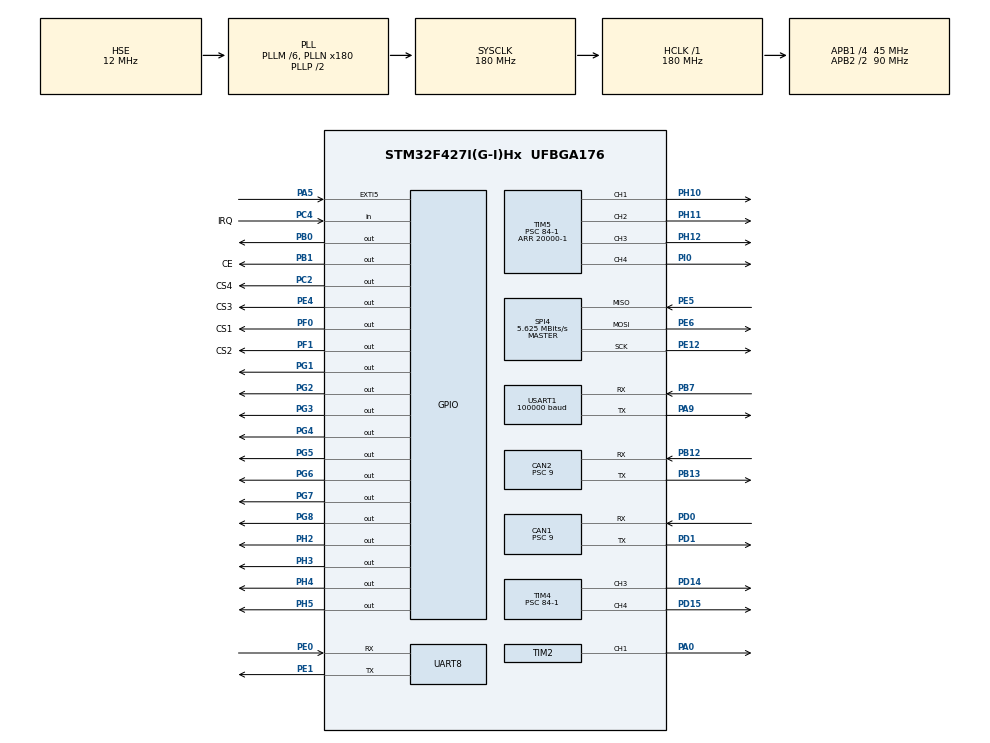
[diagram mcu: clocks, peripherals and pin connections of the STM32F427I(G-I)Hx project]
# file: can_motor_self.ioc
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CAN1.ABOM=DISABLE
CAN1.AWUM=DISABLE
CAN1.BS1=CAN_BS1_2TQ
CAN1.BS2=CAN_BS2_2TQ
CAN1.CalculateBaudRate=1000000
CAN1.CalculateTimeBit=1000
CAN1.CalculateTimeQuantum=200.0
CAN1.Prescaler=9
CAN1.TTCM=DISABLE
CAN2.BS1=CAN_BS1_2TQ
CAN2.BS2=CAN_BS2_2TQ
CAN2.CalculateBaudRate=1000000
CAN2.CalculateTimeBit=1000
CAN2.CalculateTimeQuantum=200.0
CAN2.Prescaler=9
Dma.Request0=UART8_TX
Dma.Request1=UART8_RX
Dma.Request2=SPI4_RX
Dma.Request3=SPI4_TX
Dma.SPI4_RX.2.Direction=DMA_PERIPH_TO_MEMORY
Dma.SPI4_RX.2.FIFOMode=DMA_FIFOMODE_DISABLE
Dma.SPI4_RX.2.Instance=DMA2_Stream0
Dma.SPI4_RX.2.MemDataAlignment=DMA_MDATAALIGN_HALFWORD
Dma.SPI4_RX.2.MemInc=DMA_MINC_ENABLE
Dma.SPI4_RX.2.Mode=DMA_NORMAL
Dma.SPI4_RX.2.PeriphDataAlignment=DMA_PDATAALIGN_HALFWORD
Dma.SPI4_RX.2.PeriphInc=DMA_PINC_DISABLE
Dma.SPI4_RX.2.Priority=DMA_PRIORITY_LOW
Dma.SPI4_TX.3.Direction=DMA_MEMORY_TO_PERIPH
Dma.SPI4_TX.3.FIFOMode=DMA_FIFOMODE_DISABLE
Dma.SPI4_TX.3.Instance=DMA2_Stream1
Dma.SPI4_TX.3.MemDataAlignment=DMA_MDATAALIGN_HALFWORD
Dma.SPI4_TX.3.MemInc=DMA_MINC_ENABLE
Dma.SPI4_TX.3.Mode=DMA_NORMAL
Dma.SPI4_TX.3.PeriphDataAlignment=DMA_PDATAALIGN_HALFWORD
Dma.SPI4_TX.3.PeriphInc=DMA_PINC_DISABLE
Dma.SPI4_TX.3.Priority=DMA_PRIORITY_LOW
Dma.UART8_RX.1.Direction=DMA_PERIPH_TO_MEMORY
Dma.UART8_RX.1.FIFOMode=DMA_FIFOMODE_DISABLE
Dma.UART8_RX.1.Instance=DMA1_Stream6
Dma.UART8_RX.1.MemDataAlignment=DMA_MDATAALIGN_BYTE
Dma.UART8_RX.1.MemInc=DMA_MINC_ENABLE
Dma.UART8_RX.1.Mode=DMA_NORMAL
Dma.UART8_RX.1.PeriphDataAlignment=DMA_PDATAALIGN_BYTE
Dma.UART8_RX.1.PeriphInc=DMA_PINC_DISABLE
Dma.UART8_RX.1.Priority=DMA_PRIORITY_VERY_HIGH
Dma.UART8_TX.0.Direction=DMA_MEMORY_TO_PERIPH
Dma.UART8_TX.0.FIFOMode=DMA_FIFOMODE_DISABLE
Dma.UART8_TX.0.Instance=DMA1_Stream0
Dma.UART8_TX.0.MemDataAlignment=DMA_MDATAALIGN_BYTE
Dma.UART8_TX.0.MemInc=DMA_MINC_ENABLE
Dma.UART8_TX.0.Mode=DMA_NORMAL
Dma.UART8_TX.0.PeriphDataAlignment=DMA_PDATAALIGN_BYTE
Dma.UART8_TX.0.PeriphInc=DMA_PINC_DISABLE
Dma.UART8_TX.0.Priority=DMA_PRIORITY_VERY_HIGH
Mcu.Family=STM32F4
Mcu.Name=STM32F427I(G-I)Hx
Mcu.Package=UFBGA176
NVIC.CAN1_RX0_IRQn=true\:0\:0\:false\:false\:true\:true\:true\:true
NVIC.CAN2_RX0_IRQn=true\:0\:0\:false\:false\:true\:true\:true\:true
NVIC.DMA1_Stream0_IRQn=true\:0\:0\:false\:false\:true\:false\:true\:true
NVIC.DMA1_Stream6_IRQn=true\:0\:0\:false\:false\:true\:false\:true\:true
NVIC.DMA2_Stream0_IRQn=true\:0\:0\:false\:false\:true\:false\:true\:true
NVIC.DMA2_Stream1_IRQn=true\:0\:0\:false\:false\:true\:false\:true\:true
NVIC.PriorityGroup=NVIC_PRIORITYGROUP_4
NVIC.SPI4_IRQn=true\:0\:0\:false\:false\:true\:true\:true\:true
NVIC.TIM1_UP_TIM10_IRQn=true\:15\:0\:false\:false\:true\:false\:true\:true
NVIC.TimeBase=TIM1_UP_TIM10_IRQn
NVIC.TimeBaseIP=TIM1
NVIC.UART8_IRQn=true\:0\:0\:false\:false\:true\:true\:true\:true
NVIC.USART1_IRQn=true\:0\:0\:false\:false\:true\:true\:true\:true
PA0/WKUP.Signal=S_TIM2_CH1_ETR
PA1.Signal=S_TIM2_CH2
PA13.Mode=Serial_Wire
PA13.Signal=SYS_JTMS-SWDIO
PA14.Mode=Serial_Wire
PA14.Signal=SYS_JTCK-SWCLK
PA2.Signal=S_TIM2_CH3
PA5.Signal=GPXTI5
PA9.Mode=Asynchronous
PA9.Signal=USART1_TX
PB0.PinState=GPIO_PIN_SET
PB0.Signal=GPIO_Output
PB1.GPIO_Label=CE
PB1.GPIO_PuPd=GPIO_PULLUP
PB1.GPIO_Speed=GPIO_SPEED_FREQ_HIGH
PB1.PinState=GPIO_PIN_SET
PB1.Signal=GPIO_Output
PB12.Mode=CAN_Activate
PB12.Signal=CAN2_RX
PB13.Mode=CAN_Activate
PB13.Signal=CAN2_TX
PB7.Mode=Asynchronous
PB7.Signal=USART1_RX
PC14/OSC32_IN.Mode=LSE-External-Oscillator
PC14/OSC32_IN.Signal=RCC_OSC32_IN
PC15/OSC32_OUT.Mode=LSE-External-Oscillator
PC15/OSC32_OUT.Signal=RCC_OSC32_OUT
PC2.GPIO_Label=CS4
PC2.GPIO_ModeDefaultOutputPP=GPIO_MODE_OUTPUT_PP
PC2.GPIO_PuPd=GPIO_PULLUP
PC2.GPIO_Speed=GPIO_SPEED_FREQ_HIGH
PC2.PinState=GPIO_PIN_SET
PC2.Signal=GPIO_Output
PC4.GPIO_Label=IRQ
PC4.GPIO_PuPd=GPIO_PULLUP
PC4.Signal=GPIO_Input
PD0.Mode=CAN_Activate
PD0.Signal=CAN1_RX
PD1.Mode=CAN_Activate
PD1.Signal=CAN1_TX
PD14.Signal=S_TIM4_CH3
PD15.Signal=S_TIM4_CH4
PE0.Mode=Asynchronous
PE0.Signal=UART8_RX
PE1.Mode=Asynchronous
PE1.Signal=UART8_TX
PE12.Mode=Full_Duplex_Master
PE12.Signal=SPI4_SCK
PE4.GPIO_Label=CS3
PE4.GPIO_PuPd=GPIO_PULLUP
PE4.GPIO_Speed=GPIO_SPEED_FREQ_HIGH
PE4.PinState=GPIO_PIN_SET
PE4.Signal=GPIO_Output
PE5.Mode=Full_Duplex_Master
PE5.Signal=SPI4_MISO
PE6.Mode=Full_Duplex_Master
PE6.Signal=SPI4_MOSI
PE7.Signal=UART7_RX
PE8.Signal=UART7_TX
PF0.GPIO_Label=CS1
PF0.GPIO_PuPd=GPIO_PULLUP
PF0.GPIO_Speed=GPIO_SPEED_FREQ_HIGH
PF0.PinState=GPIO_PIN_SET
PF0.Signal=GPIO_Output
PF1.GPIO_Label=CS2
PF1.GPIO_PuPd=GPIO_PULLUP
PF1.GPIO_Speed=GPIO_SPEED_FREQ_HIGH
PF1.PinState=GPIO_PIN_SET
PF1.Signal=GPIO_Output
PG1.GPIO_ModeDefaultOutputPP=GPIO_MODE_OUTPUT_PP
PG1.GPIO_PuPd=GPIO_PULLUP
PG1.Signal=GPIO_Output
PG2.Signal=GPIO_Output
PG3.Signal=GPIO_Output
PG4.Signal=GPIO_Output
PG5.Signal=GPIO_Output
PG6.Signal=GPIO_Output
PG7.Signal=GPIO_Output
PG8.Signal=GPIO_Output
PH0/OSC_IN.Mode=HSE-External-Oscillator
PH0/OSC_IN.Signal=RCC_OSC_IN
PH1/OSC_OUT.Mode=HSE-External-Oscillator
PH1/OSC_OUT.Signal=RCC_OSC_OUT
PH10.Signal=S_TIM5_CH1
PH11.Signal=S_TIM5_CH2
PH12.Signal=S_TIM5_CH3
PH2.GPIO_PuPd=GPIO_PULLUP
PH2.Signal=GPIO_Output
PH3.GPIO_PuPd=GPIO_PULLUP
PH3.Signal=GPIO_Output
PH4.GPIO_PuPd=GPIO_PULLUP
PH4.PinState=GPIO_PIN_SET
PH4.Signal=GPIO_Output
PH5.GPIO_PuPd=GPIO_PULLUP
PH5.PinState=GPIO_PIN_RESET
PH5.Signal=GPIO_Output
PI0.Signal=S_TIM5_CH4
ProjectManager.HeapSize=0x200
ProjectManager.StackSize=0x400
ProjectManager.TargetToolchain=MDK-ARM V5.32
RCC.48MHZClocksFreq_Value=90000000
RCC.AHBFreq_Value=180000000
RCC.APB1CLKDivider=RCC_HCLK_DIV4
RCC.APB1Freq_Value=45000000
RCC.APB1TimFreq_Value=90000000
RCC.APB2CLKDivider=RCC_HCLK_DIV2
RCC.APB2Freq_Value=90000000
RCC.APB2TimFreq_Value=180000000
RCC.CortexFreq_Value=180000000
RCC.HCLKFreq_Value=180000000
RCC.HSE_VALUE=12000000
RCC.HSI_VALUE=16000000
RCC.PLLM=6
RCC.PLLN=180
RCC.PLLSourceVirtual=RCC_PLLSOURCE_HSE
RCC.SYSCLKFreq_VALUE=180000000
RCC.SYSCLKSource=RCC_SYSCLKSOURCE_PLLCLK
RCC.VCOOutputFreq_Value=360000000
SH.S_TIM2_CH1_ETR.0=TIM2_CH1,PWM Generation1 CH1
SH.S_TIM2_CH2.0=TIM2_CH2
SH.S_TIM2_CH3.0=TIM2_CH3
SH.S_TIM4_CH3.0=TIM4_CH3,PWM Generation3 CH3
SH.S_TIM4_CH4.0=TIM4_CH4,PWM Generation4 CH4
SH.S_TIM5_CH1.0=TIM5_CH1,PWM Generation1 CH1
SH.S_TIM5_CH2.0=TIM5_CH2,PWM Generation2 CH2
SH.S_TIM5_CH3.0=TIM5_CH3,PWM Generation3 CH3
SH.S_TIM5_CH4.0=TIM5_CH4,PWM Generation4 CH4
SPI4.BaudRatePrescaler=SPI_BAUDRATEPRESCALER_16
SPI4.CLKPhase=SPI_PHASE_2EDGE
SPI4.CLKPolarity=SPI_POLARITY_LOW
SPI4.CRCCalculation=SPI_CRCCALCULATION_DISABLE
SPI4.CalculateBaudRate=5.625 MBits/s
SPI4.DataSize=SPI_DATASIZE_16BIT
SPI4.Direction=SPI_DIRECTION_2LINES
SPI4.Mode=SPI_MODE_MASTER
SPI4.VirtualType=VM_MASTER
TIM2.AutoReloadPreload=TIM_AUTORELOAD_PRELOAD_ENABLE
TIM2.Channel-PWM\ Generation1\ CH1=TIM_CHANNEL_1
TIM2.Period=2000
TIM2.Prescaler=180-1
TIM2.Pulse-PWM\ Generation1\ CH1=0
TIM4.AutoReloadPreload=TIM_AUTORELOAD_PRELOAD_ENABLE
TIM4.Channel-PWM\ Generation3\ CH3=TIM_CHANNEL_3
TIM4.Channel-PWM\ Generation4\ CH4=TIM_CHANNEL_4
TIM4.Period=20000-1
TIM4.Prescaler=84-1
TIM5.AutoReloadPreload=TIM_AUTORELOAD_PRELOAD_ENABLE
TIM5.Channel-PWM\ Generation1\ CH1=TIM_CHANNEL_1
TIM5.Channel-PWM\ Generation2\ CH2=TIM_CHANNEL_2
TIM5.Channel-PWM\ Generation3\ CH3=TIM_CHANNEL_3
TIM5.Channel-PWM\ Generation4\ CH4=TIM_CHANNEL_4
TIM5.Period=20000-1
TIM5.Prescaler=84-1
UART8.VirtualMode=Asynchronous
USART1.BaudRate=100000
USART1.Mode=MODE_RX
USART1.VirtualMode=VM_ASYNC
VP_SYS_VS_tim1.Mode=TIM1
VP_TIM2_VS_ClockSourceINT.Mode=Internal
board=custom

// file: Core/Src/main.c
/* USER CODE BEGIN Header */
/**
  ******************************************************************************
  * @file           : main.c
  * @brief          : Main program body
  ******************************************************************************
  * @attention
  *
  * Copyright (c) 2024 STMicroelectronics.
  * All rights reserved.
  *
  * This software is licensed under terms that can be found in the LICENSE file
  * in the root directory of this software component.
  * If no LICENSE file comes with this software, it is provided AS-IS.
  *
  ******************************************************************************
  */
/* USER CODE END Header */
#include "main.h"
#include "can.h"
#include "dma.h"
#include "spi.h"
#include "tim.h"
#include "usart.h"
#include "gpio.h"

/* USER CODE BEGIN Includes */

#include "spi5012.h"
/* USER CODE END Includes */

/* USER CODE BEGIN PV */
float angle_v[4];
/* USER CODE END PV */

void SystemClock_Config(void);

int main(void)
{

  /* MCU Configuration--------------------------------------------------------*/

  /* Reset of all peripherals, Initializes the Flash interface and the Systick. */
  HAL_Init();

  /* Configure the system clock */
  SystemClock_Config();

  /* Initialize all configured peripherals */
  MX_GPIO_Init();
  MX_DMA_Init();
  MX_CAN1_Init();
  MX_TIM2_Init();
  MX_SPI4_Init();
  MX_TIM5_Init();
  MX_USART1_UART_Init();
  MX_CAN2_Init();
  MX_TIM4_Init();
  MX_UART8_Init();

  /* Infinite loop */
  /* USER CODE BEGIN WHILE */
//	chassis_init(&chassis_move);

  while (1)
  {
		angle_v[0] = ReadRegister(0);
		angle_v[1] = ReadRegister(1);
		angle_v[2] = ReadRegister(2);
		angle_v[3] = ReadRegister(3);
		HAL_Delay(1);

    /* USER CODE END WHILE */

  }
}

void SystemClock_Config(void)
{
  RCC_OscInitTypeDef RCC_OscInitStruct = {0};
  RCC_ClkInitTypeDef RCC_ClkInitStruct = {0};

  /** Configure the main internal regulator output voltage
  */
  __HAL_RCC_PWR_CLK_ENABLE();
  __HAL_PWR_VOLTAGESCALING_CONFIG(PWR_REGULATOR_VOLTAGE_SCALE1);

  /** Initializes the RCC Oscillators according to the specified parameters
  * in the RCC_OscInitTypeDef structure.
  */
  RCC_OscInitStruct.OscillatorType = RCC_OSCILLATORTYPE_HSE;
  RCC_OscInitStruct.HSEState = RCC_HSE_ON;
  RCC_OscInitStruct.PLL.PLLState = RCC_PLL_ON;
  RCC_OscInitStruct.PLL.PLLSource = RCC_PLLSOURCE_HSE;
  RCC_OscInitStruct.PLL.PLLM = 6;
  RCC_OscInitStruct.PLL.PLLN = 180;
  RCC_OscInitStruct.PLL.PLLP = RCC_PLLP_DIV2;
  RCC_OscInitStruct.PLL.PLLQ = 4;
  if (HAL_RCC_OscConfig(&RCC_OscInitStruct) != HAL_OK)
  {
    Error_Handler();
  }

  /** Activate the Over-Drive mode
  */
  if (HAL_PWREx_EnableOverDrive() != HAL_OK)
  {
    Error_Handler();
  }

  /** Initializes the CPU, AHB and APB buses clocks
  */
  RCC_ClkInitStruct.ClockType = RCC_CLOCKTYPE_HCLK|RCC_CLOCKTYPE_SYSCLK
                              |RCC_CLOCKTYPE_PCLK1|RCC_CLOCKTYPE_PCLK2;
  RCC_ClkInitStruct.SYSCLKSource = RCC_SYSCLKSOURCE_PLLCLK;
  RCC_ClkInitStruct.AHBCLKDivider = RCC_SYSCLK_DIV1;
  RCC_ClkInitStruct.APB1CLKDivider = RCC_HCLK_DIV4;
  RCC_ClkInitStruct.APB2CLKDivider = RCC_HCLK_DIV2;

  if (HAL_RCC_ClockConfig(&RCC_ClkInitStruct, FLASH_LATENCY_5) != HAL_OK)
  {
    Error_Handler();
  }
}

/* USER CODE BEGIN 4 */

void HAL_UART_RxCpltCallback(UART_HandleTypeDef *huart)
{
	if(huart->Instance == UART8)
	{

	}
}
/* USER CODE END 4 */

void HAL_TIM_PeriodElapsedCallback(TIM_HandleTypeDef *htim)
{
  if (htim->Instance == TIM1) {
    HAL_IncTick();
  }
}

void Error_Handler(void)
{
  __disable_irq();
  while (1)
  {
  }
}
